AUTOSAR XML (schema 4-2-1)
package /Interface
  sender receiver interface SRI_EgoSpeed_AppSWC
    data EgoSpeed_AppSWC: type=float64
  sender receiver interface SRI_EgoSpeed_SASWC
    data EgoSpeed_SASWC: type=float64
  sender receiver interface SRI_EgoSpeed_IOSWC
    data EgoSpeed_IOSWC: type=float64
package /SWC
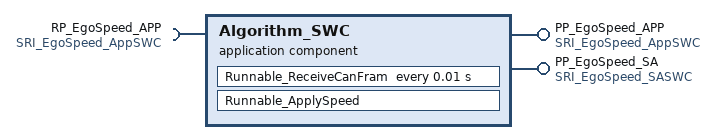
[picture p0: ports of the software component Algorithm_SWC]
  application sw component type Algorithm_SWC
    require port RP_EgoSpeed_APP: required-interface=SRI_EgoSpeed_AppSWC
    provide port PP_EgoSpeed_APP: provided-interface=SRI_EgoSpeed_AppSWC
    provide port PP_EgoSpeed_SA: provided-interface=SRI_EgoSpeed_SASWC
    behavior Behavior_AEB
      timing event TimingEvent_10ms: start-on-event=Runnable_ReceiveCanFram, period=0.01
      data received event Data_receiveEvent1: start-on-event=Runnable_ApplySpeed, data=RP_EgoSpeed_APP.EgoSpeed_AppSWC
      runnable Runnable_ReceiveCanFram
        data-write-access:
          access speed: accessed-variable=PP_EgoSpeed_APP.EgoSpeed_AppSWC
      runnable Runnable_ApplySpeed
        data-read-access:
          access speed_procees: accessed-variable=RP_EgoSpeed_APP.EgoSpeed_AppSWC
        data-write-access:
          access SpeedProcess: accessed-variable=PP_EgoSpeed_SA.EgoSpeed_SASWC
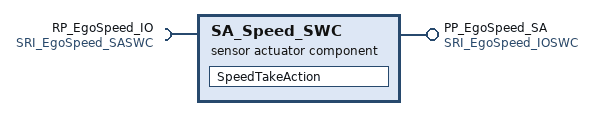
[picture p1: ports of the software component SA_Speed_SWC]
  sensor actuator sw component type SA_Speed_SWC
    provide port PP_EgoSpeed_SA: provided-interface=SRI_EgoSpeed_IOSWC
    require port RP_EgoSpeed_IO: required-interface=SRI_EgoSpeed_SASWC
    behavior Behavior_SA
      data received event DataReceiveEvent2: start-on-event=SpeedTakeAction, data=RP_EgoSpeed_IO.EgoSpeed_SASWC
      runnable SpeedTakeAction
        data-read-access:
          access Speed_st: accessed-variable=RP_EgoSpeed_IO.EgoSpeed_SASWC
        data-write-access:
          access speed_St: accessed-variable=PP_EgoSpeed_SA.EgoSpeed_IOSWC
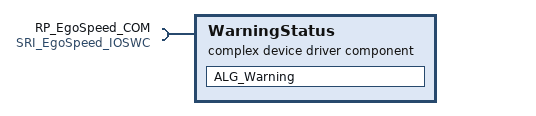
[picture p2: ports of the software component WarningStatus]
  complex device driver sw component type WarningStatus
    require port RP_EgoSpeed_COM: required-interface=SRI_EgoSpeed_IOSWC
    behavior Behavior_COM
      data received event DataReceiveEvent3: start-on-event=ALG_Warning, data=RP_EgoSpeed_COM.EgoSpeed_IOSWC
      runnable ALG_Warning
        data-read-access:
          access Speed_st: accessed-variable=RP_EgoSpeed_COM.EgoSpeed_IOSWC
